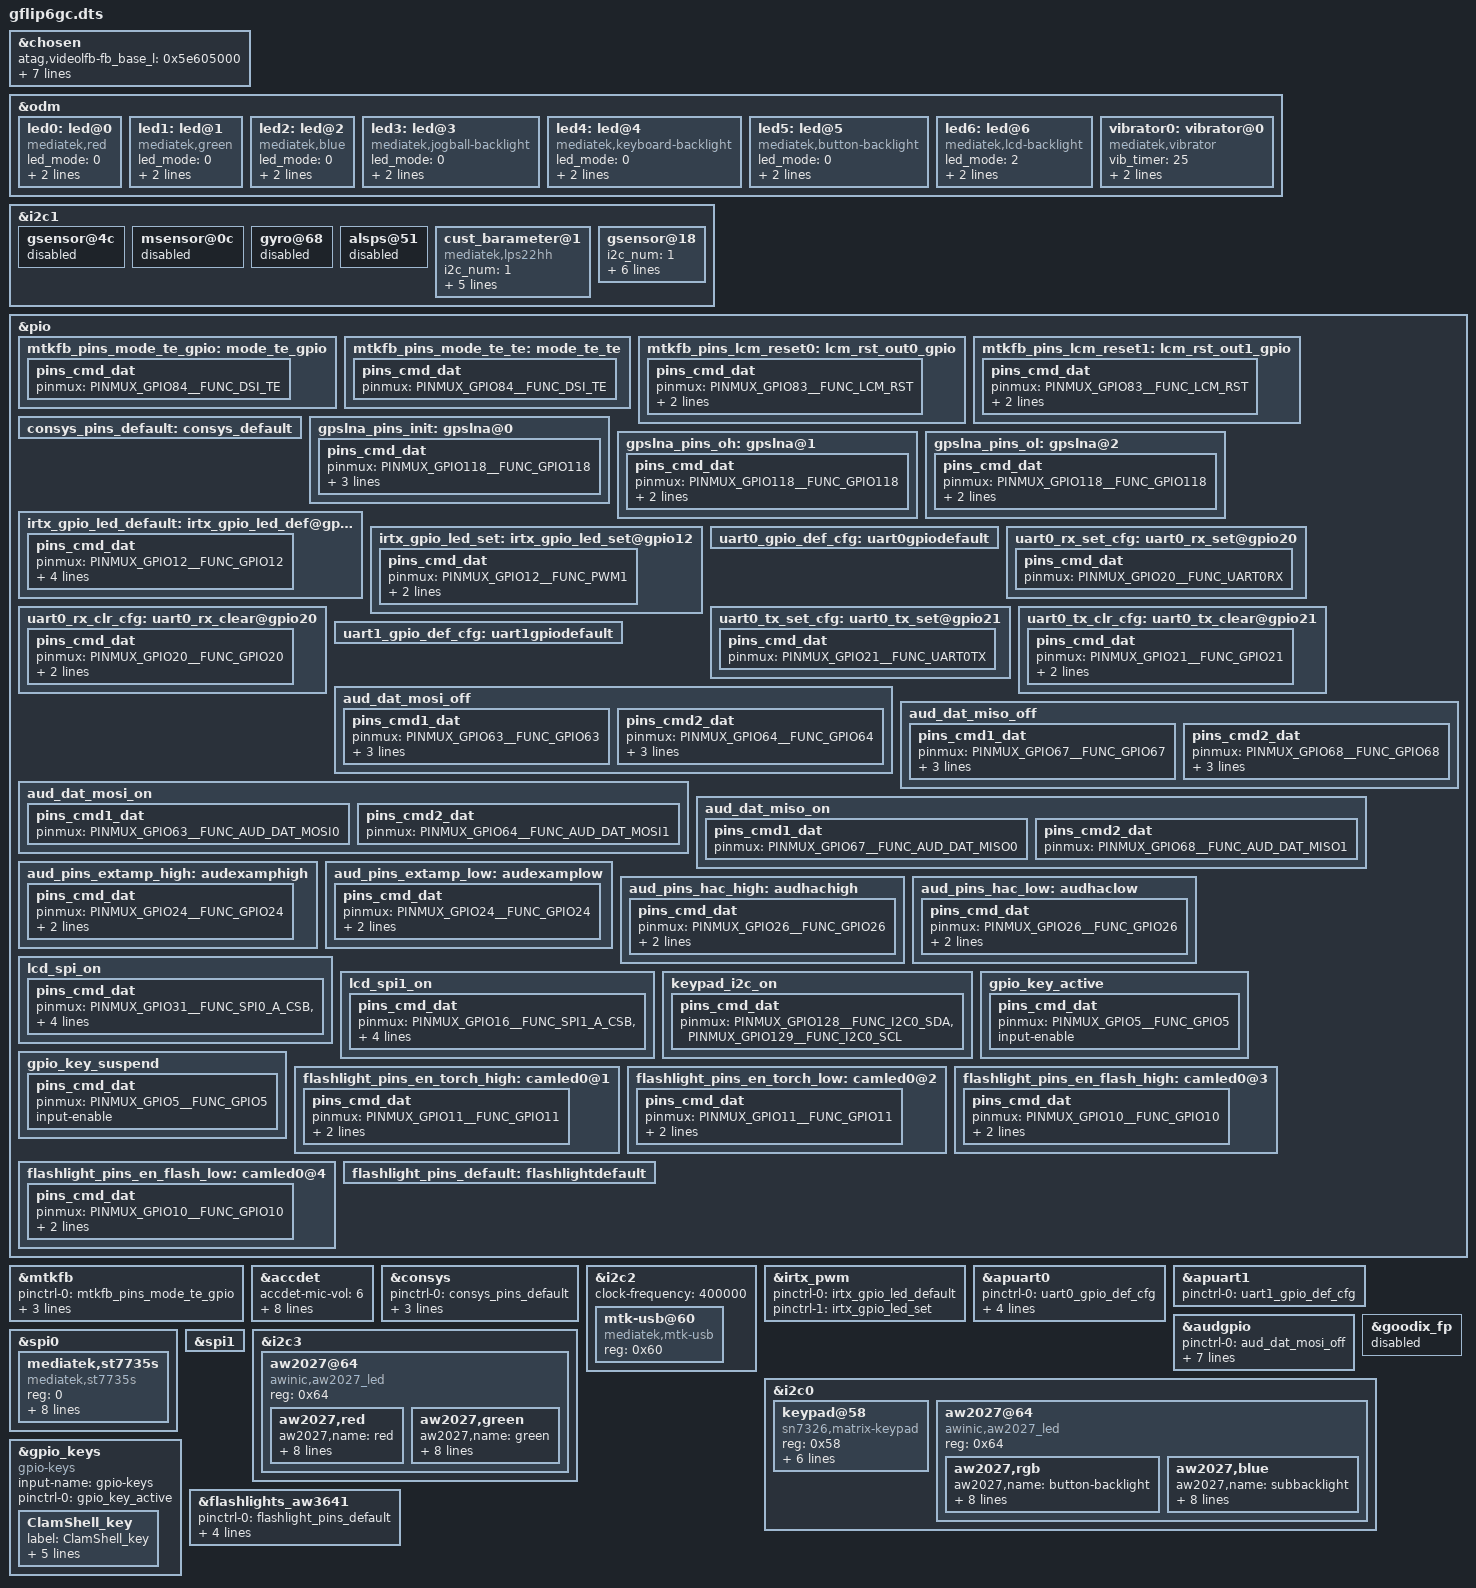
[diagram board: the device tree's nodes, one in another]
#include <generated/autoconf.h>
/dts-v1/;

/plugin/;
#include <dt-bindings/mmc/mt6739-msdc.h>
#include <dt-bindings/pinctrl/mt6739-pinfunc.h>
#include <dt-bindings/interrupt-controller/arm-gic.h>
#include <dt-bindings/interrupt-controller/irq.h>

/* chosen */
&chosen {
	/* fpga may has no lk, we need to specify display info here */
	/* fb buffer is reserved using this dts by memory node above */

	atag,videolfb-fb_base_l = <0x5e605000>;
	atag,videolfb-fb_base_h = <0>;
	atag,videolfb-islcmfound = <1>;
	atag,videolfb-islcm_inited = <0>;
	atag,videolfb-fps= <6000>;
	atag,videolfb-vramSize= <0x017bb000>;
	atag,videolfb-lcmname= "nt35521_hd_dsi_vdo_truly_nt50358_drv";
};

&odm {
	led0:led@0 {
		compatible = "mediatek,red";
		led_mode = <0>;
		data = <1>;
		pwm_config = <0 0 0 0 0>;
	};
	led1:led@1 {
		compatible = "mediatek,green";
		led_mode = <0>;
		data = <1>;
		pwm_config = <0 0 0 0 0>;
	};
	led2:led@2 {
		compatible = "mediatek,blue";
		led_mode = <0>;
		data = <1>;
		pwm_config = <0 0 0 0 0>;
	};
	led3:led@3 {
		compatible = "mediatek,jogball-backlight";
		led_mode = <0>;
		data = <1>;
		pwm_config = <0 0 0 0 0>;
	};
	led4:led@4 {
		compatible = "mediatek,keyboard-backlight";
		led_mode = <0>;
		data = <1>;
		pwm_config = <0 0 0 0 0>;
	};
	led5:led@5 {
		compatible = "mediatek,button-backlight";
		led_mode = <0>;
		data = <1>;
		pwm_config = <0 0 0 0 0>;
	};
	led6:led@6 {
		compatible = "mediatek,lcd-backlight";
		led_mode = <2>;
		data = <428>;
		pwm_config = <0 2 0 0 0>;
	};
	vibrator0:vibrator@0 {
		compatible = "mediatek,vibrator";
		vib_timer = <25>;
		vib_limit = <9>;
		vib_vol= <11>;
	};
};

&i2c1 {
/*  start sensor */
	gsensor@4c {
		status = "disabled";
	};

	msensor@0c {
		status = "disabled";
	};

	gyro@68 {
		status = "disabled";
	};

	alsps@51 {
		status = "disabled";
	};
        cust_barameter@1 {
                compatible = "mediatek,lps22hh";
	 	i2c_num= <1>;
                direction = <1>;
                power_id = <0xffff>;
                power_vol = <0>;
                firlen = <1>;
                is_batch_supported = <1>;
         };
    gsensor@18 {
 		i2c_num = <1>;
 		i2c_addr = <0x18 0 0 0>;
 		direction = <6>;
 		power_id = <0xffff>;
 		power_vol = <0>;
 		firlen = <0>;
 		is_batch_supported = <0>;
 	};
/* end sensor */
};

/* DISPSYS GPIO standardization */
&pio {
	mtkfb_pins_mode_te_gpio: mode_te_gpio {
		pins_cmd_dat {
			pinmux = <PINMUX_GPIO84__FUNC_DSI_TE>;
		};
	};

	mtkfb_pins_mode_te_te: mode_te_te {
		pins_cmd_dat {
			pinmux = <PINMUX_GPIO84__FUNC_DSI_TE>;
		};
	};

	mtkfb_pins_lcm_reset0: lcm_rst_out0_gpio {
		pins_cmd_dat {
			pinmux = <PINMUX_GPIO83__FUNC_LCM_RST>;
			slew-rate = <1>;
			output-low;
		};
	};

	mtkfb_pins_lcm_reset1: lcm_rst_out1_gpio {
		pins_cmd_dat {
			pinmux = <PINMUX_GPIO83__FUNC_LCM_RST>;
			slew-rate = <1>;
			output-high;
		};
	};
};

&mtkfb {
	pinctrl-names = "mode_te_gpio", "mode_te_te", "lcm_rst_out0_gpio",
		"lcm_rst_out1_gpio";
	pinctrl-0 = <&mtkfb_pins_mode_te_gpio>;
	pinctrl-1 = <&mtkfb_pins_mode_te_te>;
	pinctrl-2 = <&mtkfb_pins_lcm_reset0>;
	pinctrl-3 = <&mtkfb_pins_lcm_reset1>;
	status = "okay";
};
/* DISPSYS GPIO standardization end */


/* accdet start */
&accdet {
	/* accdet micbias voltage: 0x07,2.7v;0x05,2.5v;0x02,1.9v */
	accdet-mic-vol = <6>;
	headset-mode-setting = <0x500 0x500 1 0x1f0 0x800 0x800 0x20 0x44>;
	accdet-plugout-debounce = <1>;
	/*1:ACC mode, 2:low cost without in bias, 6:low cost with in bias*/
	accdet-mic-mode = <1>;
/* eint_level_trigger: 8,LEVEL_LOW(default);4,LEVEL_HIGH;others,LEVEL_LOW */
	headset-eint-level-pol = <8>;
	/*0--MD_MAX--UP_MAX--DW_MAX*/
	headset-three-key-threshold = <0 80 220 400>;
	headset-three-key-threshold-CDD = <0 121 192 600>;
	/*0--MD_MAX--VOICE_MAX--UP_MAX--DW_MAX*/
	headset-four-key-threshold = <0 58 121 192 400>;
	status = "okay";
};
/* accdet end */

/* CONSYS GPIO standardization */
&pio {
	consys_pins_default: consys_default {
	};
	gpslna_pins_init: gpslna@0 {
		pins_cmd_dat {
			pinmux = <PINMUX_GPIO118__FUNC_GPIO118>;
			slew-rate = <0>;
			bias-disable;
			output-low;
		};
	};
	gpslna_pins_oh: gpslna@1 {
		pins_cmd_dat {
			pinmux = <PINMUX_GPIO118__FUNC_GPIO118>;
			slew-rate = <1>;
			output-high;
		};
	};
	gpslna_pins_ol: gpslna@2 {
		pins_cmd_dat {
			pinmux = <PINMUX_GPIO118__FUNC_GPIO118>;
			slew-rate = <1>;
			output-low;
		};
	};
};
&consys {
	pinctrl-names = "default", "gps_lna_state_init",
			"gps_lna_state_oh", "gps_lna_state_ol";
	pinctrl-0 = <&consys_pins_default>;
	pinctrl-1 = <&gpslna_pins_init>;
	pinctrl-2 = <&gpslna_pins_oh>;
	pinctrl-3 = <&gpslna_pins_ol>;
	status = "okay";
};
&i2c2 {
	#address-cells = <1>;
	#size-cells = <0>;
	clock-frequency = <400000>;

	mtk-usb@60 {
		compatible = "mediatek,mtk-usb";
		reg = <0x60>;
		status = "okay";
	};
};

/* IRTX GPIO Start */
&irtx_pwm {
	pinctrl-names = "irtx_gpio_led_default", "irtx_gpio_led_set";
	pinctrl-0 = <&irtx_gpio_led_default>;
	pinctrl-1 = <&irtx_gpio_led_set>;
	status = "okay";
};
&pio {
	/* IRTX GPIO Settings -Start */
	/* default: GPIO0, output, high */
	irtx_gpio_led_default:irtx_gpio_led_def@gpio12 {
		pins_cmd_dat {
			pinmux = <PINMUX_GPIO12__FUNC_GPIO12>;
			slew-rate = <1>;
			bias-disable;
			output-low;
			input-schmitt-enable = <0>;
		};
	};

	irtx_gpio_led_set:irtx_gpio_led_set@gpio12 {
		pins_cmd_dat {
			pinmux = <PINMUX_GPIO12__FUNC_PWM1>;
			slew-rate = <1>;
			output-high;
		};
	};
}; /* IRTX GPIO Settings -End */

/* UART GPIO */
&apuart0 {
	pinctrl-names = "uart0_gpio_default",
			"uart0_rx_set",
			"uart0_rx_clear",
			"uart0_tx_set",
			"uart0_tx_clear";
	pinctrl-0 = <&uart0_gpio_def_cfg>;
	pinctrl-1 = <&uart0_rx_set_cfg>;
	pinctrl-2 = <&uart0_rx_clr_cfg>;
	pinctrl-3 = <&uart0_tx_set_cfg>;
	pinctrl-4 = <&uart0_tx_clr_cfg>;
	status = "okay";
};

&apuart1 {
	pinctrl-names = "uart1_gpio_default";
	pinctrl-0 = <&uart1_gpio_def_cfg>;
	status = "okay";
};

&pio {
	/* UART GPIO Settings - Start */
	/* UART0: rx set, rx clear, tx clear, tx clear*/
	uart0_gpio_def_cfg:uart0gpiodefault {

	};
	uart0_rx_set_cfg:uart0_rx_set@gpio20 {
		pins_cmd_dat {
			pinmux = <PINMUX_GPIO20__FUNC_UART0RX>;
		};
	};
	uart0_rx_clr_cfg:uart0_rx_clear@gpio20 {
		pins_cmd_dat {
			pinmux = <PINMUX_GPIO20__FUNC_GPIO20>;
			slew-rate = <1>;
			output-high;
		};
	};
	uart0_tx_set_cfg:uart0_tx_set@gpio21 {
		pins_cmd_dat {
			pinmux = <PINMUX_GPIO21__FUNC_UART0TX>;
		};
	};
	uart0_tx_clr_cfg:uart0_tx_clear@gpio21 {
		pins_cmd_dat {
			pinmux = <PINMUX_GPIO21__FUNC_GPIO21>;
			slew-rate = <1>;
			output-high;
		};
	};
	/* UART1: rx set, rx clear, tx clear, tx clear*/
	uart1_gpio_def_cfg:uart1gpiodefault {

	};
};/* UART GPIO end */

/* AUDIO GPIO standardization */
&audgpio {
	pinctrl-names = "aud_dat_mosi_off",
			"aud_dat_mosi_on",
			"aud_dat_miso_off",
			"aud_dat_miso_on",
			"extamp-pullhigh",
			"extamp-pulllow",
/*wanying.chen add for hac 2022.1.5*/
			"hac_pins_on",
			"hac_pins_off";
/*wanying.chen add for hac 2022.1.5*/
	pinctrl-0 = <&aud_dat_mosi_off>;
	pinctrl-1 = <&aud_dat_mosi_on>;
	pinctrl-2 = <&aud_dat_miso_off>;
	pinctrl-3 = <&aud_dat_miso_on>;
	pinctrl-4 = <&aud_pins_extamp_high>;
	pinctrl-5 = <&aud_pins_extamp_low>;
/*wanying.chen add for hac 2022.1.5*/
	pinctrl-6 = <&aud_pins_hac_high>;
	pinctrl-7 = <&aud_pins_hac_low>;
/*wanying.chen add for hac 2022.1.5*/
	status = "okay";
};

&pio {
	aud_dat_mosi_off: aud_dat_mosi_off {
		pins_cmd1_dat {
			pinmux = <PINMUX_GPIO63__FUNC_GPIO63>;
			input-enable;
			slew-rate = <0>;
			bias-disable;
		};
		pins_cmd2_dat {
			pinmux = <PINMUX_GPIO64__FUNC_GPIO64>;
			input-enable;
			slew-rate = <0>;
			bias-disable;
		};
	};

	aud_dat_mosi_on: aud_dat_mosi_on {
		pins_cmd1_dat {
			pinmux = <PINMUX_GPIO63__FUNC_AUD_DAT_MOSI0>;
		};
		pins_cmd2_dat {
			pinmux = <PINMUX_GPIO64__FUNC_AUD_DAT_MOSI1>;
		};
	};

	aud_dat_miso_off: aud_dat_miso_off {
		pins_cmd1_dat {
			pinmux = <PINMUX_GPIO67__FUNC_GPIO67>;
			input-enable;
			slew-rate = <0>;
			bias-disable;
		};
		pins_cmd2_dat {
			pinmux = <PINMUX_GPIO68__FUNC_GPIO68>;
			input-enable;
			slew-rate = <0>;
			bias-disable;
		};
	};

	aud_dat_miso_on: aud_dat_miso_on {
		pins_cmd1_dat {
			pinmux = <PINMUX_GPIO67__FUNC_AUD_DAT_MISO0>;
		};
		pins_cmd2_dat {
			pinmux = <PINMUX_GPIO68__FUNC_AUD_DAT_MISO1>;
		};
	};
	aud_pins_extamp_high: audexamphigh {
		pins_cmd_dat {
			pinmux = <PINMUX_GPIO24__FUNC_GPIO24>;
			slew-rate = <1>;
			output-high;
		};
	};

	aud_pins_extamp_low: audexamplow {
		pins_cmd_dat {
			pinmux = <PINMUX_GPIO24__FUNC_GPIO24>;
			slew-rate = <1>;
			output-low;
		};
	};
	/* Begin modify by wanying.chen for hac on 20220104*/
 	aud_pins_hac_high: audhachigh {
 		pins_cmd_dat {
 			pinmux = <PINMUX_GPIO26__FUNC_GPIO26>;
 			slew-rate=<1>;
 			output-high;
 		};
 	};
 
 	aud_pins_hac_low: audhaclow {
 		pins_cmd_dat {
 			pinmux = <PINMUX_GPIO26__FUNC_GPIO26>;
 			slew-rate=<1>;
 			output-low;
 		};
 	};
 	/* Begin modify by wanying.chen for hac on 20220104*/

};
/* AUDIO end */

&goodix_fp {
	status = "disabled";
};

&pio {
	lcd_spi_on:lcd_spi_on{
		pins_cmd_dat{
			pinmux = <PINMUX_GPIO31__FUNC_SPI0_A_CSB>,
			<PINMUX_GPIO32__FUNC_SPI0_A_CLK>,
			<PINMUX_GPIO33__FUNC_SPI0_A_MI>,
			<PINMUX_GPIO34__FUNC_SPI0_A_MO>;
			drive-strength = <3>;
		};
	};

        lcd_spi1_on:lcd_spi1_on{
                pins_cmd_dat{
                        pinmux = <PINMUX_GPIO16__FUNC_SPI1_A_CSB>,
                        <PINMUX_GPIO17__FUNC_SPI1_A_CLK>,
                        <PINMUX_GPIO18__FUNC_SPI1_A_MI>,
                        <PINMUX_GPIO19__FUNC_SPI1_A_MO>;
                        drive-strength = <3>;
                };
        };
};

&spi0 {
	#address-cells = <1>;
	#size-cells = <0>;

        /*lcd_spi@0 {
                compatible = "mediatek,lcd-spi-display";
                reg = <0>;
                spi-max-frequency = <56000000>;
		pinctrl-names = "state_spi_all";
		pinctrl-0 = <&lcd_spi_on>;
                lcm-te-gpio = <&pio 83 0x0>;
                lcm-rst-gpio = <&pio 25 0x0>;
		lcm-wrx-gpio = <&pio 23 0x0>;
                lcm-id0-gpio = <&pio 110 0x0>;
		lcm-id1-gpio = <&pio 111 0x0>;
                lcm-width = <240>;
                lcm-height = <320>;
                lcm-bpp = <16>;
                status = "okay";
        };*/
		
     	status = "okay";
	mediatek,st7735s {
		reg = <0>;
		compatible = "mediatek,st7735s";
		label = "fbtft st7735s";
		spi-max-frequency = <10000000>;
		buswidth = <8>;
		bgr;
		pinctrl-names = "state_spi_all";
		pinctrl-0 = <&lcd_spi_on>;
		reset-gpios = <&pio 122 1>;
		dc-gpios = <&pio 23 0>;
		id-gpios = <&pio 107 0>,<&pio 106 0>;
	};

};


&spi1 {
	/*status = "okay";
	mediatek,st7735s {
		reg = <0>;
		compatible = "mediatek,st7735s";
		label = "fbtft st7735s";
		spi-max-frequency = <10000000>;
		buswidth = <8>;
		bgr;
		pinctrl-names = "state_spi_all";
		pinctrl-0 = <&lcd_spi1_on>;
		reset-gpios = <&pio 122 1>;
		dc-gpios = <&pio 13 0>;
		id-gpios = <&pio 107 0>,<&pio 106 0>;
	};*/
};

&pio {
	keypad_i2c_on:keypad_i2c_on{
		pins_cmd_dat{
			pinmux = <PINMUX_GPIO128__FUNC_I2C0_SDA>,<PINMUX_GPIO129__FUNC_I2C0_SCL>;
		};
	};
};
&i2c0 {
	status = "okay";
	keypad@58 {
		compatible = "sn7326,matrix-keypad";
		reg = <0x58>;
		pinctrl-names = "state_i2c_all";
		pinctrl-0 = <&keypad_i2c_on>;
		interrupt-parent = <&pio>;
		interrupts = <6 IRQ_TYPE_EDGE_FALLING 6 0>;
		sn,rest-gpio = <&pio 22 0x00>;
                /* Modify-start by baiwei.peng for gflip6v_gc matrix keypad on 2022/11/10 */
                sn7326,keymap-value= <0x1106c 0x0209e /*0x5208a*/ 0x43067 0x3001c 0x5308a /*0x5101e*/ 0x4206a 0x23069 0x4103b /*0x4009e*/
                                       0x31002 0x33003 0x32004 0x13006 0x10005 0x12007 0x03009 0x8 0x0100a 0x2020a 0x2220b 0x2100b >;
                /* Modify-end by baiwei.peng for gflip6v_gc matrix keypad on 2022/11/10 */
	};
	
};

&i2c0 {
	status = "okay";
	aw2027@64 {
		compatible = "awinic,aw2027_led";
		reg = <0x64>;

		aw2027,rgb {
			aw2027,name = "button-backlight";
			aw2027,id = <3>;
			/* MODIFIED-BEGIN by hongwei.tian, 2019-05-17,BUG-7776080*/
			aw2027,imax = <0>;
			aw2027,led-current = <0xaff>;
			/* MODIFIED-END by hongwei.tian,BUG-7776080*/
			aw2027,max-brightness = <255>;
			aw2027,rise-time-ms = <6>;
			aw2027,hold-time-ms = <0>;
			aw2027,fall-time-ms = <6>;
			aw2027,off-time-ms = <4>;
		};

		aw2027,blue {
			aw2027,name = "subbacklight";
			aw2027,id = <4>;
			aw2027,imax = <1>;
			aw2027,led-current = <0xbbb>; // MODIFIED by hongwei.tian, 2019-05-17,BUG-7776080
			aw2027,max-brightness = <255>;
			aw2027,rise-time-ms = <6>;
			aw2027,hold-time-ms = <0>;
			aw2027,fall-time-ms = <6>;
			aw2027,off-time-ms = <4>;
		};
	};
};

/* Add-start by baiwei.peng for charging leds porting on 2021/01/24 */
&i2c3 {
	status = "okay";
	aw2027@64 {
		compatible = "awinic,aw2027_led";
		reg = <0x64>;

		aw2027,red {
			aw2027,name = "red";
			aw2027,id = <1>;
			aw2027,imax = <1>;
			aw2027,led-current = <0x001>; // MODIFIED by hongwei.tian, 2019-05-17,BUG-7776080
			aw2027,max-brightness = <232>;
			aw2027,rise-time-ms = <6>;
			aw2027,hold-time-ms = <0>;
			aw2027,fall-time-ms = <6>;
			aw2027,off-time-ms = <4>;
		};

		aw2027,green {
			aw2027,name = "green";
			aw2027,id = <2>;
			aw2027,imax = <1>;
			aw2027,led-current = <0x010>; // MODIFIED by hongwei.tian, 2019-05-17,BUG-7776080
			aw2027,max-brightness = <255>;
			aw2027,rise-time-ms = <6>;
			aw2027,hold-time-ms = <0>;
			aw2027,fall-time-ms = <6>;
			aw2027,off-time-ms = <4>;
		};
	};
};
/* Add-end by baiwei.peng for charging leds porting on 2021/01/24 */

&pio {
	gpio_key_active: gpio_key_active {
		pins_cmd_dat {
			pinmux = <PINMUX_GPIO5__FUNC_GPIO5>;
			input-enable;
		};
	};

	gpio_key_suspend: gpio_key_suspend {
		pins_cmd_dat {
			pinmux = <PINMUX_GPIO5__FUNC_GPIO5>;
			input-enable;
		};
	};
};

&gpio_keys {
	compatible = "gpio-keys";
	input-name = "gpio-keys";
	pinctrl-names = "default";
	pinctrl-0 = <&gpio_key_active>;

	ClamShell_key {
	     	label = "ClamShell_key";
	     	gpios = <&pio 5 0x1>;
	     	linux,input-type = <1>;
	     	linux,code = <252>;
	     	gpio-key,wakeup;
	     	debounce-interval = <15>;
	};
};

/* flash light */
&pio {
		flashlight_pins_en_torch_high: camled0@1 {
		    pins_cmd_dat {
				pinmux = <PINMUX_GPIO11__FUNC_GPIO11>;
				slew-rate = <1>;
				output-high;
			};
		};
		flashlight_pins_en_torch_low: camled0@2 {
		    pins_cmd_dat {
				pinmux = <PINMUX_GPIO11__FUNC_GPIO11>;
				slew-rate = <1>;
				output-low;
			};
		};
		flashlight_pins_en_flash_high: camled0@3 {
		    pins_cmd_dat {
				pinmux = <PINMUX_GPIO10__FUNC_GPIO10>;
				slew-rate = <1>;
				output-high;
			};
		};
		flashlight_pins_en_flash_low: camled0@4 {
		    pins_cmd_dat {
				pinmux = <PINMUX_GPIO10__FUNC_GPIO10>;
				slew-rate = <1>;
				output-low;
			};
		};
		flashlight_pins_default: flashlightdefault {
		};
};

&flashlights_aw3641 {
	pinctrl-names = "default", "en_torch_high", "en_torch_low","en_flash_high", "en_flash_low";
	pinctrl-0 = <&flashlight_pins_default>;
	pinctrl-1 = <&flashlight_pins_en_torch_high>;
	pinctrl-2 = <&flashlight_pins_en_torch_low>;
	pinctrl-3 = <&flashlight_pins_en_flash_high>;
	pinctrl-4 = <&flashlight_pins_en_flash_low>;
	status = "okay";

};
/* flash light end*/

#include "bat_setting/gflip6gc/gflip6_mt6739_battery_prop_ext.dtsi"
#include "bat_setting/gflip6gc/gflip6_charger.dtsi"
#include <gflip6gc/cust.dtsi>
#include "cust_mt6739_camera.dtsi"
/*End of this file, DO NOT ADD ANYTHING HERE*/
